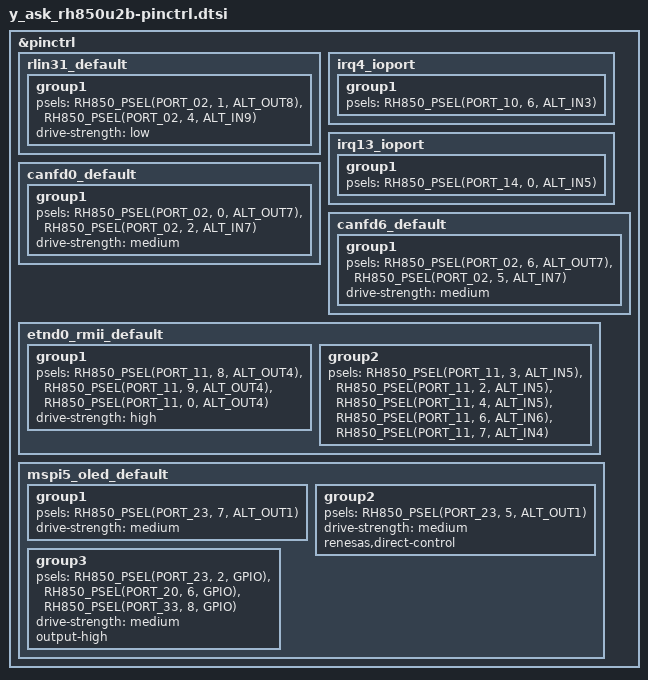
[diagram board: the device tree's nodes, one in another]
/*
 * Copyright (c) 2026 Renesas Electronics Corporation
 * SPDX-License-Identifier: Apache-2.0
 */

#include <dt-bindings/pinctrl/renesas/pinctrl-rh850u2b.h>

&pinctrl {
	rlin31_default: rlin31_default {
		group1 {
			psels = <RH850_PSEL(PORT_02, 1, ALT_OUT8)>,
				<RH850_PSEL(PORT_02, 4, ALT_IN9)>;
			drive-strength = "low";
		};
	};

	irq4_ioport: irq4_ioport {
		group1 {
			psels = <RH850_PSEL(PORT_10, 6, ALT_IN3)>;
		};
	};

	irq13_ioport: irq13_ioport {
		group1 {
			psels = <RH850_PSEL(PORT_14, 0, ALT_IN5)>;
		};
	};

	canfd0_default: canfd0_default {
		group1 {
			psels = <RH850_PSEL(PORT_02, 0, ALT_OUT7)>,	/* TX */
				<RH850_PSEL(PORT_02, 2, ALT_IN7)>;	/* RX */
			drive-strength = "medium";
		};
	};

	canfd6_default: canfd6_default {
		group1 {
			psels = <RH850_PSEL(PORT_02, 6, ALT_OUT7)>,	/* TX */
				<RH850_PSEL(PORT_02, 5, ALT_IN7)>;	/* RX */
			drive-strength = "medium";
		};
	};

	etnd0_rmii_default: etnd0_rmii_default {
		group1 {
			psels = <RH850_PSEL(PORT_11, 8, ALT_OUT4)>,	/* ETH0_RMII_TXD0 */
				<RH850_PSEL(PORT_11, 9, ALT_OUT4)>,	/* ETH0_RMII_TXD1 */
				<RH850_PSEL(PORT_11, 0, ALT_OUT4)>;	/* ETH0_RMII_TX_EN */
			drive-strength = "high";
		};

		group2 {
			psels = <RH850_PSEL(PORT_11, 3, ALT_IN5)>,	/* ETH0_RMII_RXD0 */
				<RH850_PSEL(PORT_11, 2, ALT_IN5)>,	/* ETH0_RMII_RXD1 */
				<RH850_PSEL(PORT_11, 4, ALT_IN5)>,	/* ETH0_MII_TX_CLK */
				<RH850_PSEL(PORT_11, 6, ALT_IN6)>,	/* ETH0_RMII_ER */
				<RH850_PSEL(PORT_11, 7, ALT_IN4)>;	/* ETH0_RMII_RX_DV */
		};
	};

	mspi5_oled_default: mspi5_oled_default {
		group1 {
			/* OLED SCLK: P23_7, output in master mode. */
			psels = <RH850_PSEL(PORT_23, 7, ALT_OUT1)>;
			drive-strength = "medium";
		};

		group2 {
			/* OLED MOSI: P23_5, MSPI5SO. */
			psels = <RH850_PSEL(PORT_23, 5, ALT_OUT1)>;
			drive-strength = "medium";
			renesas,direct-control;
		};

		group3 {
			/* OLED CS#: P23_2; D/C#: P20_6; RESET#: P33_8. */
			psels = <RH850_PSEL(PORT_23, 2, GPIO)>,
				<RH850_PSEL(PORT_20, 6, GPIO)>,
				<RH850_PSEL(PORT_33, 8, GPIO)>;
			drive-strength = "medium";
			output-high;
		};
	};
};
